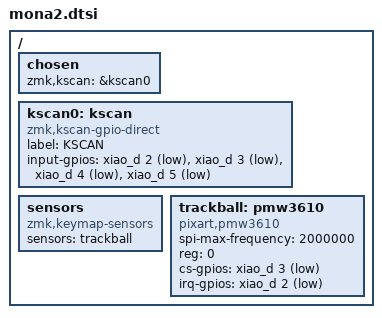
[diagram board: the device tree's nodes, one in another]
#include <dt-bindings/zmk/matrix_transform.h>

/ {
    chosen {
        zmk,kscan = &kscan0;
    };

    kscan0: kscan {
        compatible = "zmk,kscan-gpio-direct";
        label = "KSCAN";
        input-gpios
            = <&xiao_d 2 (GPIO_ACTIVE_LOW | GPIO_PULL_UP)>
            , <&xiao_d 3 (GPIO_ACTIVE_LOW | GPIO_PULL_UP)>
            , <&xiao_d 4 (GPIO_ACTIVE_LOW | GPIO_PULL_UP)>
            , <&xiao_d 5 (GPIO_ACTIVE_LOW | GPIO_PULL_UP)>
            ;
    };

    sensors {
        compatible = "zmk,keymap-sensors";
        sensors = <&trackball>;
    };

    trackball: pmw3610 {
        compatible = "pixart,pmw3610";
        spi-max-frequency = <2000000>;
        reg = <0>;
        cs-gpios = <&xiao_d 3 GPIO_ACTIVE_LOW>;
        irq-gpios = <&xiao_d 2 (GPIO_ACTIVE_LOW | GPIO_PULL_UP)>;
    };
};
